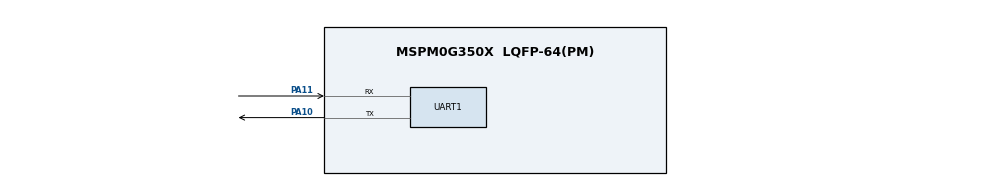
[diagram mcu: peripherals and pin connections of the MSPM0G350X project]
/**
 * @cliArgs --device "MSPM0G350X" --part "Default" --package "LQFP-64(PM)" --product "mspm0_sdk@2.09.00.00"
 * @versions {"tool":"1.26.0+4407"}
 */

/**
 * Import the modules used in this configuration.
 */
const GPIO   = scripting.addModule("/ti/driverlib/GPIO", {}, false);
const GPIO1  = GPIO.addInstance();
const SYSCTL = scripting.addModule("/ti/driverlib/SYSCTL");
const UART   = scripting.addModule("/ti/driverlib/UART", {}, false);
const UART1  = UART.addInstance();

/**
 * Write custom configuration values to the imported modules.
 */
GPIO1.$name                          = "GPIO_LED";
GPIO1.associatedPins[0].$name        = "LED_PIN_1";
GPIO1.associatedPins[0].assignedPort = "PORTB";
GPIO1.associatedPins[0].assignedPin  = "22";

const Board = scripting.addModule("/ti/driverlib/Board", {}, false);

SYSCTL.clockTreeEn           = true;
SYSCTL.forceDefaultClkConfig = true;

UART1.$name                             = "UART_0";
UART1.enableFIFO                        = true;
UART1.rxFifoThreshold                   = "DL_UART_RX_FIFO_LEVEL_ONE_ENTRY";
UART1.enableDMARX                       = false;
UART1.enableInternalLoopback            = false;
UART1.txFifoThreshold                   = "DL_UART_TX_FIFO_LEVEL_ONE_ENTRY";
UART1.enabledDMATXTriggers              = "DL_UART_DMA_INTERRUPT_TX";
UART1.enableDMATX                       = true;
UART1.targetBaudRate                    = 115200;
UART1.enabledInterrupts                 = ["DMA_DONE_TX"];
UART1.peripheral.$assign                = "UART0";
UART1.peripheral.rxPin.$assign          = "PA11";
UART1.peripheral.txPin.$assign          = "PA10";
UART1.txPinConfig.$name                 = "ti_driverlib_gpio_GPIOPinGeneric0";
UART1.rxPinConfig.$name                 = "ti_driverlib_gpio_GPIOPinGeneric1";
UART1.DMA_CHANNEL_TX.$name              = "DMA_CH0";
UART1.DMA_CHANNEL_TX.addressMode        = "b2f";
UART1.DMA_CHANNEL_TX.dstLength          = "BYTE";
UART1.DMA_CHANNEL_TX.srcLength          = "BYTE";
UART1.DMA_CHANNEL_TX.peripheral.$assign = "DMA_CH0";

/**
 * Pinmux solution for unlocked pins/peripherals. This ensures that minor changes to the automatic solver in a future
 * version of the tool will not impact the pinmux you originally saw.  These lines can be completely deleted in order to
 * re-solve from scratch.
 */
GPIO1.associatedPins[0].pin.$suggestSolution = "PB22";
Board.peripheral.$suggestSolution            = "DEBUGSS";
Board.peripheral.swclkPin.$suggestSolution   = "PA20";
Board.peripheral.swdioPin.$suggestSolution   = "PA19";
